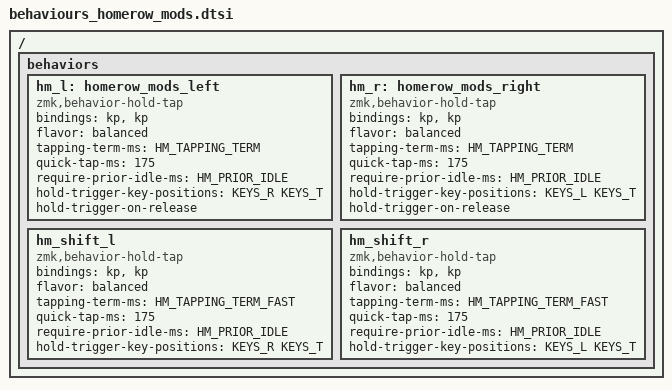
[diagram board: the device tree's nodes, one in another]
// Make sure settings.dtsi is included before this file


#define KEYS_L LT0 LT1 LT2 LT3 LT4 LT5 LM0 LM1 LM2 LM3 LM4 LM5 LB0 LB1 LB2 LB3 LB4 LB5  // left-hand keys
#define KEYS_R RT0 RT1 RT2 RT3 RT4 RT5 RM0 RM1 RM2 RM3 RM4 RM5 RB0 RB1 RB2 RB3 RB4 RB5// right-hand keys
#define KEYS_T LH2 LH1 LH0 RH0 RH1 RH2                                      // thumb keys

#define HM_TAPPING_TERM 300
#define HM_TAPPING_TERM_FAST 200
#define HM_PRIOR_IDLE 150

/ {

    behaviors {

        // Positional Homerow mods
        // Homerow mods that prevent accidental activations when rolling keys,
        // such as when typing `st` or `ne` on colemak-dh layouts or `as` on
        // qwerty.
        //
        // Works by only allowing a mod to activate within tapping-term if
        // it's on the opposite side of the keyboard or on the same side thumb
        // keys.

        // Further optimization using urob's timerless homerow mods method:
        // https://github.com/urob/zmk-config#timeless-homerow-mods
        hm_l: homerow_mods_left {
            compatible = "zmk,behavior-hold-tap";
            #binding-cells = <2>;
            bindings = <&kp>,  <&kp>;

            flavor = "balanced";
            tapping-term-ms = <HM_TAPPING_TERM>;
            quick-tap-ms = <175>;                // repeat on tap-into-hold
            require-prior-idle-ms = <HM_PRIOR_IDLE>;

            hold-trigger-key-positions = <KEYS_R KEYS_T>;
            hold-trigger-on-release;
        };

        hm_r: homerow_mods_right {
            compatible = "zmk,behavior-hold-tap";
            #binding-cells = <2>;
            bindings = <&kp>, <&kp>;

            flavor = "balanced";
            tapping-term-ms = <HM_TAPPING_TERM>;
            quick-tap-ms = <175>;
            require-prior-idle-ms = <HM_PRIOR_IDLE>;

            hold-trigger-key-positions = <KEYS_L KEYS_T>;
            hold-trigger-on-release;
        };


        // Positional Homerow mods for shift
        // Use faster tapping term and disable some features that may
        // cause false negatives.
        hm_shift_l: hm_shift_l {
            compatible = "zmk,behavior-hold-tap";
            #binding-cells = <2>;
            bindings = <&kp>, <&kp>;

            flavor = "balanced";
            tapping-term-ms = <HM_TAPPING_TERM_FAST>;
            quick-tap-ms = <175>;
            require-prior-idle-ms = <HM_PRIOR_IDLE>;

            hold-trigger-key-positions = <KEYS_R KEYS_T>;
            // hold-trigger-on-release;
        };

        hm_shift_r: hm_shift_r {
            compatible = "zmk,behavior-hold-tap";
            #binding-cells = <2>;
            bindings = <&kp>, <&kp>;

            flavor = "balanced";
            tapping-term-ms = <HM_TAPPING_TERM_FAST>;
            quick-tap-ms = <175>;
            require-prior-idle-ms = <HM_PRIOR_IDLE>;

            hold-trigger-key-positions = <KEYS_L KEYS_T>;
            // hold-trigger-on-release;
        };
    };
};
